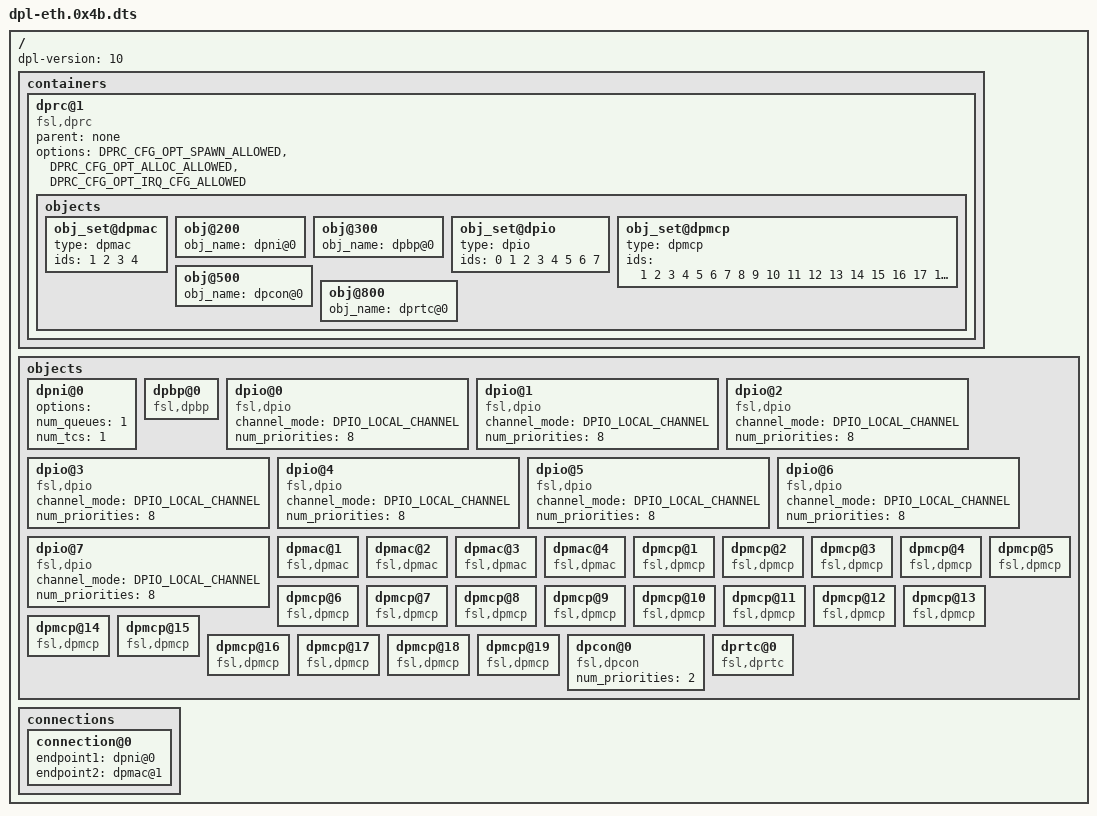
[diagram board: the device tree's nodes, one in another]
/*
 * Copyright 2017 NXP
 *
 * Redistribution and use in source and binary forms, with or without
 * modification, are permitted provided that the following conditions are met:
 *   * Redistributions of source code must retain the above copyright
 *     notice, this list of conditions and the following disclaimer.
 *   * Redistributions in binary form must reproduce the above copyright
 *     notice, this list of conditions and the following disclaimer in the
 *     documentation and/or other materials provided with the distribution.
 *   * Neither the name of the above-listed copyright holders nor the
 *     names of any contributors may be used to endorse or promote products
 *     derived from this software without specific prior written permission.
 *
 * THIS SOFTWARE IS PROVIDED BY THE COPYRIGHT HOLDERS AND CONTRIBUTORS "AS IS"
 * AND ANY EXPRESS OR IMPLIED WARRANTIES, INCLUDING, BUT NOT LIMITED TO, THE
 * IMPLIED WARRANTIES OF MERCHANTABILITY AND FITNESS FOR A PARTICULAR PURPOSE
 * ARE DISCLAIMED. IN NO EVENT SHALL THE COPYRIGHT HOLDERS OR CONTRIBUTORS BE
 * LIABLE FOR ANY DIRECT, INDIRECT, INCIDENTAL, SPECIAL, EXEMPLARY, OR
 * CONSEQUENTIAL DAMAGES (INCLUDING, BUT NOT LIMITED TO, PROCUREMENT OF
 * SUBSTITUTE GOODS OR SERVICES; LOSS OF USE, DATA, OR PROFITS; OR BUSINESS
 * INTERRUPTION) HOWEVER CAUSED AND ON ANY THEORY OF LIABILITY, WHETHER IN
 * CONTRACT, STRICT LIABILITY, OR TORT (INCLUDING NEGLIGENCE OR OTHERWISE)
 * ARISING IN ANY WAY OUT OF THE USE OF THIS SOFTWARE, EVEN IF ADVISED OF THE
 * POSSIBILITY OF SUCH DAMAGE.
 */

/*
 * "Bootstrap DPL" for ls2081a RDB boards featuring SerDes 0x4b.
 * This DPL defines one network interface mapped on the ETH0 optical port.
 * This together with the available DPMCP objects should be enough to boot Linux
 * and to allow the dynamic addition of other objects to the Linux container,
 * using the 'restool' utility.
 */

/dts-v1/;
/ {
	dpl-version = <10>;
	/*****************************************************************
	 * Containers
	 *****************************************************************/
	containers {
		dprc@1 {
			compatible = "fsl,dprc";
			parent = "none";
			options = "DPRC_CFG_OPT_SPAWN_ALLOWED" , "DPRC_CFG_OPT_ALLOC_ALLOWED", "DPRC_CFG_OPT_IRQ_CFG_ALLOWED";
			objects {
				/* ------------- MACs --------------*/
				obj_set@dpmac {
					type = "dpmac";
					ids = <1 2 3 4>;
				};

				/* ------------ DPNIs --------------*/
				obj@200 {
					obj_name = "dpni@0";
				};

				/* ------------ DPBPs --------------*/
				obj@300 {
					obj_name="dpbp@0";
				};

				/* ------------ DPIOs --------------*/
				obj_set@dpio {
					type = "dpio";
					ids = <0 1 2 3 4 5 6 7>;
				};

				/* ------------ DPMCPs --------------*/
				obj_set@dpmcp {
					type = "dpmcp";
					ids = <1 2 3 4 5 6 7 8 9 10 11 12 13 14 15 16 17 18 19>;
				};

				/* ------------ DPCON --------------*/
				obj@500 {
					obj_name="dpcon@0";
				};

				/* ------------ DPRTC --------------*/
				obj@800 {
					obj_name="dprtc@0";
				};
			};
		};
	};

	/*****************************************************************
	 * Objects
	 *****************************************************************/
	objects {

		/* ------------ DPNI --------------*/
		dpni@0 {
			options = "";
			num_queues = <1>;
			num_tcs = <1>;
		};

		/* ------------ DPBP --------------*/
		dpbp@0 {
			compatible="fsl,dpbp";
		};

		/* ------------ DPIO --------------*/
		dpio@0 {
			compatible = "fsl,dpio";
			channel_mode = "DPIO_LOCAL_CHANNEL";
			num_priorities = <8>;
		};
		dpio@1 {
			compatible = "fsl,dpio";
			channel_mode = "DPIO_LOCAL_CHANNEL";
			num_priorities = <8>;
		};
		dpio@2 {
			compatible = "fsl,dpio";
			channel_mode = "DPIO_LOCAL_CHANNEL";
			num_priorities = <8>;
		};
		dpio@3 {
			compatible = "fsl,dpio";
			channel_mode = "DPIO_LOCAL_CHANNEL";
			num_priorities = <8>;
		};
		dpio@4 {
			compatible = "fsl,dpio";
			channel_mode = "DPIO_LOCAL_CHANNEL";
			num_priorities = <8>;
		};
		dpio@5 {
			compatible = "fsl,dpio";
			channel_mode = "DPIO_LOCAL_CHANNEL";
			num_priorities = <8>;
		};
		dpio@6 {
			compatible = "fsl,dpio";
			channel_mode = "DPIO_LOCAL_CHANNEL";
			num_priorities = <8>;
		};
		dpio@7 {
			compatible = "fsl,dpio";
			channel_mode = "DPIO_LOCAL_CHANNEL";
			num_priorities = <8>;
		};

		/* ------------ DPMAC --------------*/
		/* For SerDes 0x4b, DPMACs 1-4 are mapped to the optical PHYs.
		 * Object IDs are relevant, as the MC firmware currently uses
		 * them to identify the DPMACs directly, so dpmac@X is actually
		 * DPMAC#X.
		 */
		dpmac@1 {
			compatible = "fsl,dpmac";
		};
		dpmac@2 {
			compatible = "fsl,dpmac";
		};
		dpmac@3 {
			compatible = "fsl,dpmac";
		};
		dpmac@4 {
			compatible = "fsl,dpmac";
		};

		/* ------------ DPMCP --------------*/
		dpmcp@1 {
			compatible="fsl,dpmcp";
		};
		dpmcp@2 {
			compatible="fsl,dpmcp";
		};
		dpmcp@3 {
			compatible="fsl,dpmcp";
		};
		dpmcp@4 {
			compatible="fsl,dpmcp";
		};
		dpmcp@5 {
			compatible="fsl,dpmcp";
		};
		dpmcp@6 {
			compatible="fsl,dpmcp";
		};
		dpmcp@7 {
			compatible="fsl,dpmcp";
		};
		dpmcp@8 {
			compatible="fsl,dpmcp";
		};
		dpmcp@9 {
			compatible="fsl,dpmcp";
		};
		dpmcp@10 {
			compatible="fsl,dpmcp";
		};
		dpmcp@11 {
			compatible="fsl,dpmcp";
		};
		dpmcp@12 {
			compatible="fsl,dpmcp";
		};
		dpmcp@13 {
			compatible="fsl,dpmcp";
		};
		dpmcp@14 {
			compatible="fsl,dpmcp";
		};
		dpmcp@15 {
			compatible="fsl,dpmcp";
		};
		dpmcp@16 {
			compatible="fsl,dpmcp";
		};
		dpmcp@17 {
			compatible="fsl,dpmcp";
		};
		dpmcp@18 {
			compatible="fsl,dpmcp";
		};
		dpmcp@19 {
			compatible="fsl,dpmcp";
		};

		/* ------------ DPCON --------------*/
		dpcon@0 {
			compatible="fsl,dpcon";
			num_priorities=<2>;
		};

		/* ------------ DPRTC --------------*/
		dprtc@0 {
			compatible="fsl,dprtc";
		};
	};

	/*****************************************************************
	 * Connections
	 *****************************************************************/
	connections {
		connection@0{
			endpoint1 = "dpni@0";
			endpoint2 = "dpmac@1";
		};
	};
};
